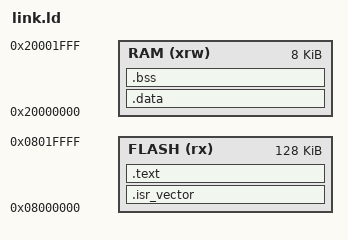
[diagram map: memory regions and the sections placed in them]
/* Entry Point */
ENTRY(Reset_Handler)

/* Specify the memory areas */
MEMORY
{
  FLASH (rx)      : ORIGIN = 0x08000000, LENGTH = 128K
  RAM (xrw)       : ORIGIN = 0x20000000, LENGTH = 8K
}

/* Highest address of the user mode stack */
_estack = ORIGIN(RAM) + LENGTH(RAM); /* end of 8K RAM */

/* Define output sections */
SECTIONS
{
  /* The startup code goes first into FLASH */
  .isr_vector :
  {
    . = ALIGN(4);
    KEEP(*(.isr_vector)) /* Startup code */
    . = ALIGN(4);
  } >FLASH

  /* The program code and other data goes into FLASH */
  .text :
  {
    . = ALIGN(4);
    *(.text)           /* .text sections (code) */
    *(.text*)          /* .text* sections (code) */
    *(.rodata)         /* .rodata sections (constants, strings, etc.) */
    *(.rodata*)        /* .rodata* sections (constants, strings, etc.) */
    . = ALIGN(4);
    _etext = .;        /* define a global symbols at end of code */
  } >FLASH

  /* used by the startup to initialize data */
  _sidata = .;

  /* Initialized data sections goes into RAM, load LMA copy after code */
  .data : AT ( _sidata )
  {
    . = ALIGN(4);
    _sdata = .;        /* create a global symbol at data start */
    *(.data)           /* .data sections */
    *(.data*)          /* .data* sections */

    . = ALIGN(4);
    _edata = .;        /* define a global symbol at data end */
  } >RAM

  /* Uninitialized data section */
  . = ALIGN(4);
  .bss :
  {
    /* This is used by the startup in order to initialize the .bss secion */
    _sbss = .;         /* define a global symbol at bss start */
    __bss_start__ = _sbss;
    *(.bss)
    *(.bss*)
    *(COMMON)

    . = ALIGN(4);
    _ebss = .;         /* define a global symbol at bss end */
    __bss_end__ = _ebss;
  } >RAM

  PROVIDE ( end = _ebss );
  PROVIDE ( _end = _ebss );

  /* Remove information from the standard libraries */
/*  /DISCARD/ :
  {
    libc.a ( * )
    libm.a ( * )
    libgcc.a ( * )
  }*/
}
